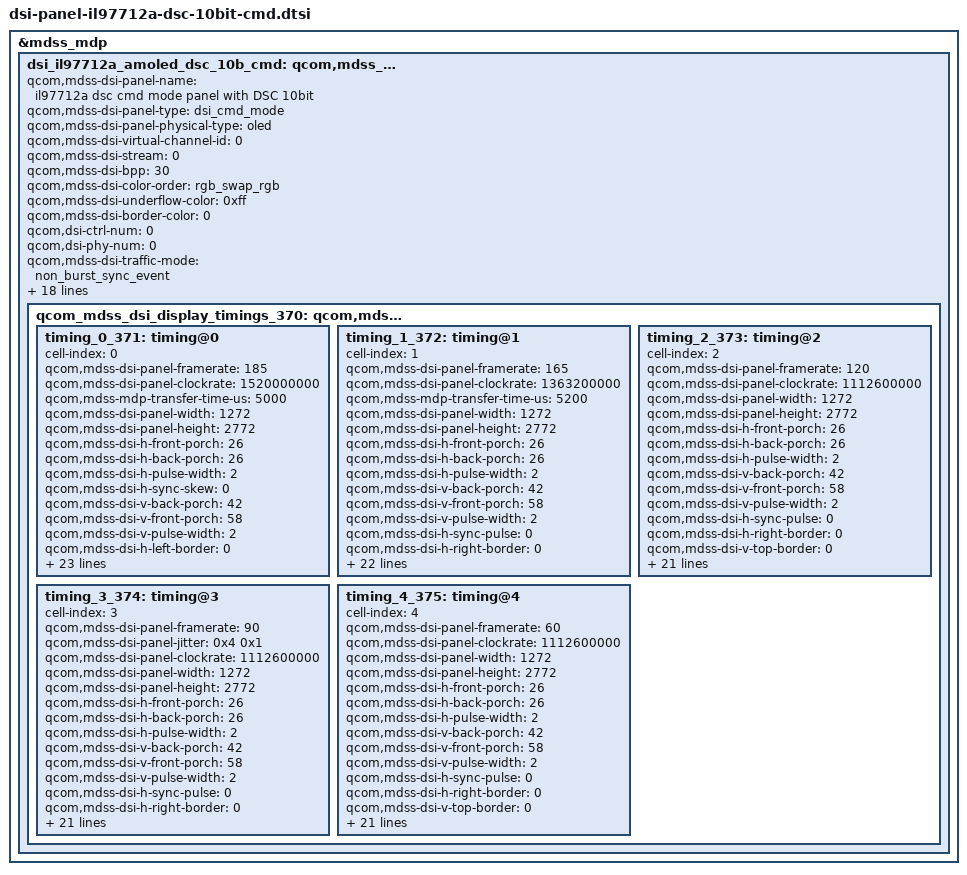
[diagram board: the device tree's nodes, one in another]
// SPDX-License-Identifier: BSD-3-Clause
/*
 * Copyright (c) Qualcomm Technologies, Inc. and/or its subsidiaries.
 */

&mdss_mdp {
	dsi_il97712a_amoled_dsc_10b_cmd: qcom,mdss_dsi_il97712a_amoled_dsc_10b_cmd {
		qcom,mdss-dsi-panel-name =
			"il97712a dsc cmd mode panel with DSC 10bit";
		qcom,mdss-dsi-panel-type = "dsi_cmd_mode";
		qcom,mdss-dsi-panel-physical-type = "oled";
		qcom,mdss-dsi-virtual-channel-id = <0>;
		qcom,mdss-dsi-stream = <0>;
		qcom,mdss-dsi-bpp = <30>;
		qcom,mdss-dsi-color-order = "rgb_swap_rgb";
		qcom,mdss-dsi-underflow-color = <0xff>;
		qcom,mdss-dsi-border-color = <0>;

		qcom,dsi-ctrl-num = <0>;
		qcom,dsi-phy-num = <0>;

		qcom,mdss-dsi-traffic-mode = "non_burst_sync_event";
		qcom,mdss-dsi-lane-map = "lane_map_0123";
		qcom,mdss-dsi-bllp-eof-power-mode;
		qcom,mdss-dsi-bllp-power-mode;
		qcom,mdss-dsi-lane-0-state;
		qcom,mdss-dsi-lane-1-state;
		qcom,mdss-dsi-lane-2-state;
		qcom,mdss-dsi-lane-3-state;
		qcom,mdss-dsi-dma-trigger = "trigger_sw";
		qcom,mdss-dsi-mdp-trigger = "none";
		qcom,mdss-dsi-reset-sequence = <1 10>, <0 10>, <1 10>;
		qcom,mdss-pan-physical-width-dimension = <71>;
		qcom,mdss-pan-physical-height-dimension = <157>;

		qcom,mdss-dsi-te-pin-select = <1>;
		qcom,mdss-dsi-wr-mem-start = <0x2c>;
		qcom,mdss-dsi-wr-mem-continue = <0x3c>;
		qcom,mdss-dsi-te-dcs-command = <1>;
		qcom,mdss-dsi-te-check-enable;
		qcom,mdss-dsi-te-using-te-pin;

		qcom_mdss_dsi_display_timings_370: qcom,mdss-dsi-display-timings {
			timing_0_371: timing@0 {
				cell-index = <0>;
				qcom,mdss-dsi-panel-framerate = <185>;
				qcom,mdss-dsi-panel-clockrate = <1520000000>;
				qcom,mdss-mdp-transfer-time-us = <5000>;
				qcom,mdss-dsi-panel-width = <1272>;
				qcom,mdss-dsi-panel-height = <2772>;
				qcom,mdss-dsi-h-front-porch = <26>;
				qcom,mdss-dsi-h-back-porch = <26>;
				qcom,mdss-dsi-h-pulse-width = <2>;
				qcom,mdss-dsi-h-sync-skew = <0>;
				qcom,mdss-dsi-v-back-porch = <42>;
				qcom,mdss-dsi-v-front-porch = <58>;
				qcom,mdss-dsi-v-pulse-width = <2>;
				qcom,mdss-dsi-h-left-border = <0>;
				qcom,mdss-dsi-h-right-border = <0>;
				qcom,mdss-dsi-v-top-border = <0>;
				qcom,mdss-dsi-v-bottom-border = <0>;
				qcom,mdss-dsi-panel-jitter = <0x4 0x1>;

				qcom,mdss-dsi-on-command = [
					39 00 00 40 00 00 04 FF 5A A5 07
					15 00 00 40 00 00 02 8A 01
					39 00 00 40 00 00 04 8B A0 00 0C
					39 00 00 00 00 00 64 81 00 00 00 00 00
					   12 00 00 AB 30 80 0A D4 04 F8 00 16
					   02 7C 02 7C 02 00 02 59 00 20 02 2E
					   00 08 00 0D 04 F4 03 ED 18 00 10 F0
					   07 10 20 00 06 0F 0F 33 0E 1C 2A 38
					   46 54 62 69 70 77 79 7B 7D 7E 02 02
					   22 00 2A 40 2A BE 3A FC 3A FA 3A F8
					   3B 38 3B 78 3B B6 4B B6 4B F4 4B F4
					   6C 34 84 74 00 00 00 00 00 00
					39 00 00 40 00 00 04 FF 5A A5 08
					15 00 00 40 00 00 02 BE 00
					15 00 00 40 00 00 02 C8 62
					39 00 00 40 00 00 04 FF 5A A5 21
					15 00 00 40 00 00 02 A4 38
					39 00 00 40 00 00 04 FF 5A A5 20
					15 00 00 40 00 00 02 C7 02
					39 00 00 40 00 00 04 FF 5A A5 00
					15 00 00 40 00 00 02 B9 01
					15 00 00 40 00 00 02 D1 08
					15 00 00 40 00 00 02 D0 00
					15 00 00 40 00 00 02 35 00
					15 00 00 40 00 00 02 53 20
					39 00 00 40 00 00 04 FF 5A A5 20
					15 00 00 40 00 00 02 C7 00
					15 00 00 40 00 00 02 D4 01
					39 00 00 40 00 00 04 FF 5A A5 00
					39 00 00 40 00 00 05 94 00 00 00 00
					39 00 00 40 00 00 04 FF 5A A5 1F
					15 00 00 40 00 00 02 80 8A
					15 00 00 40 00 00 02 81 06
					39 00 00 40 00 00 03 82 00 80
					15 00 00 40 00 00 02 87 09
					15 00 00 40 00 00 02 88 00
					39 00 00 40 00 00 06 89 41 00 04 F0 44
					39 00 00 40 00 00 03 8A 75 11
					39 00 00 40 00 00 04 8C 00 00 24
					15 00 00 40 00 00 02 8E 10
					39 00 00 40 00 00 05 96 15 35 55 01
					39 00 00 40 00 00 06 97 11 33 22 01 09
					39 00 00 40 00 00 19 83 18 24 00 00 00
					   00 00 00 00 00 00 00 00 00 00 00 00
					   00 00 00 00 00 00 00
					39 00 00 40 00 00 19 8F 39 00 00 00 00
					   00 00 00 00 00 00 00 00 00 00 00 00
					   00 00 00 00 00 00 00
					39 00 00 40 00 00 09 85 18 24 FF FF FF
					   FF FF FF
					39 00 00 40 00 00 04 91 75 00 00
					39 00 00 40 00 00 04 FF 5A A5 29
					15 00 00 40 00 00 02 80 F2
					39 00 00 40 00 00 0E 82 78 A0 B8 BC BC
					   BC BC BC BC BC BC BC BC
					39 00 00 40 00 00 0E 83 78 A0 B8 BC BC
					   BC BC BC BC BC BC BC BC
					39 00 00 40 00 00 0E 84 78 A0 B8 BC BC
					   BC BC BC BC BC BC BC BC
					39 00 00 40 00 00 0E 85 78 A0 B8 BC BC
					   BC BC BC BC BC BC BC BC
					39 00 00 00 00 00 04 FF 5A A5 00

					05 00 00 00 78 00 01 11
					05 00 00 00 14 00 01 29
				];

				qcom,mdss-dsi-off-command = [
					05 00 00 00 14 00 01 28
					05 00 00 00 78 00 01 10];
				qcom,mdss-dsi-timing-switch-command = [
					39 00 00 00 00 00 04 FF 5A A5 00
					15 00 00 40 00 00 02 D0 00
				];
				qcom,mdss-dsi-on-command-state = "dsi_lp_mode";
				qcom,mdss-dsi-off-command-state = "dsi_hs_mode";
				qcom,mdss-dsi-h-sync-pulse = <0>;
				qcom,mdss-dsi-timing-switch-command-state =
					"dsi_lp_mode";
				qcom,compression-mode = "dsc";
				qcom,mdss-dsc-version = <0x12>;
				qcom,mdss-dsc-slice-height = <22>;
				qcom,mdss-dsc-slice-width = <636>;
				qcom,mdss-dsc-slice-per-pkt = <2>;
				qcom,mdss-dsc-bit-per-component = <10>;
				qcom,mdss-dsc-bit-per-pixel = <8>;
				qcom,mdss-dsc-block-prediction-enable;
			};

			timing_1_372: timing@1 {
				cell-index = <1>;
				qcom,mdss-dsi-panel-framerate = <165>;
				qcom,mdss-dsi-panel-clockrate = <1363200000>;
				qcom,mdss-mdp-transfer-time-us = <5200>;
				qcom,mdss-dsi-panel-width = <1272>;
				qcom,mdss-dsi-panel-height = <2772>;
				qcom,mdss-dsi-h-front-porch = <26>;
				qcom,mdss-dsi-h-back-porch = <26>;
				qcom,mdss-dsi-h-pulse-width = <2>;
				qcom,mdss-dsi-v-back-porch = <42>;
				qcom,mdss-dsi-v-front-porch = <58>;
				qcom,mdss-dsi-v-pulse-width = <2>;
				qcom,mdss-dsi-h-sync-pulse = <0>;
				qcom,mdss-dsi-h-right-border = <0>;
				qcom,mdss-dsi-v-top-border = <0>;
				qcom,mdss-dsi-v-bottom-border = <0>;
				qcom,mdss-dsi-h-left-border = <0>;
				qcom,mdss-dsi-panel-jitter = <0x4 0x1>;
				qcom,mdss-dsi-on-command = [
					39 00 00 40 00 00 04 FF 5A A5 07
					15 00 00 40 00 00 02 8A 01
					39 00 00 40 00 00 04 8B A0 00 0C
					39 00 00 00 00 00 64 81 00 00 00 00 00
					   12 00 00 AB 30 80 0A D4 04 F8 00 16
					   02 7C 02 7C 02 00 02 59 00 20 02 2E
					   00 08 00 0D 04 F4 03 ED 18 00 10 F0
					   07 10 20 00 06 0F 0F 33 0E 1C 2A 38
					   46 54 62 69 70 77 79 7B 7D 7E 02 02
					   22 00 2A 40 2A BE 3A FC 3A FA 3A F8
					   3B 38 3B 78 3B B6 4B B6 4B F4 4B F4
					   6C 34 84 74 00 00 00 00 00 00
					39 00 00 40 00 00 04 FF 5A A5 08
					15 00 00 40 00 00 02 BE 00
					15 00 00 40 00 00 02 C8 62
					39 00 00 40 00 00 04 FF 5A A5 21
					15 00 00 40 00 00 02 A4 38
					39 00 00 40 00 00 04 FF 5A A5 20
					15 00 00 40 00 00 02 C7 02
					39 00 00 40 00 00 04 FF 5A A5 00
					15 00 00 40 00 00 02 B9 01
					15 00 00 40 00 00 02 D1 08
					15 00 00 40 00 00 02 D0 01
					15 00 00 40 00 00 02 35 00
					15 00 00 40 00 00 02 53 20
					39 00 00 40 00 00 04 FF 5A A5 20
					15 00 00 40 00 00 02 C7 00
					15 00 00 40 00 00 02 D4 01
					39 00 00 40 00 00 04 FF 5A A5 00
					39 00 00 40 00 00 05 94 00 00 00 00
					39 00 00 40 00 00 04 FF 5A A5 1F
					15 00 00 40 00 00 02 80 8A
					15 00 00 40 00 00 02 81 06
					39 00 00 40 00 00 03 82 00 80
					15 00 00 40 00 00 02 87 09
					15 00 00 40 00 00 02 88 00
					39 00 00 40 00 00 06 89 41 00 04 F0 44
					39 00 00 40 00 00 03 8A 75 11
					39 00 00 40 00 00 04 8C 00 00 24
					15 00 00 40 00 00 02 8E 10
					39 00 00 40 00 00 05 96 15 35 55 01
					39 00 00 40 00 00 06 97 11 33 22 01 09
					39 00 00 40 00 00 19 83 18 24 00 00 00
					   00 00 00 00 00 00 00 00 00 00 00 00
					   00 00 00 00 00 00 00
					39 00 00 40 00 00 19 8F 39 00 00 00 00
					   00 00 00 00 00 00 00 00 00 00 00 00
					   00 00 00 00 00 00 00
					39 00 00 40 00 00 09 85 18 24 FF FF FF
					   FF FF FF
					39 00 00 40 00 00 04 91 75 00 00
					39 00 00 40 00 00 04 FF 5A A5 29
					15 00 00 40 00 00 02 80 F2
					39 00 00 40 00 00 0E 82 78 A0 B8 BC BC
					   BC BC BC BC BC BC BC BC
					39 00 00 40 00 00 0E 83 78 A0 B8 BC BC
					   BC BC BC BC BC BC BC BC
					39 00 00 40 00 00 0E 84 78 A0 B8 BC BC
					   BC BC BC BC BC BC BC BC
					39 00 00 40 00 00 0E 85 78 A0 B8 BC BC
					   BC BC BC BC BC BC BC BC
					39 00 00 00 00 00 04 FF 5A A5 00

					05 00 00 00 78 00 01 11
					05 00 00 00 14 00 01 29
				];
				qcom,mdss-dsi-off-command = [
					05 00 00 00 14 00 01 28
					05 00 00 00 78 00 01 10];
				qcom,mdss-dsi-timing-switch-command = [
					39 00 00 00 00 00 04 FF 5A A5 00
					15 00 00 40 00 00 02 D0 01
				];
				qcom,mdss-dsi-on-command-state = "dsi_lp_mode";
				qcom,mdss-dsi-off-command-state = "dsi_hs_mode";
				qcom,mdss-dsi-timing-switch-command-state =
					"dsi_lp_mode";
				qcom,compression-mode = "dsc";
				qcom,mdss-dsc-version = <0x12>;
				qcom,mdss-dsc-slice-height = <22>;
				qcom,mdss-dsc-slice-width = <636>;
				qcom,mdss-dsc-slice-per-pkt = <2>;
				qcom,mdss-dsc-bit-per-component = <10>;
				qcom,mdss-dsc-bit-per-pixel = <8>;
				qcom,mdss-dsc-block-prediction-enable;
			};

			timing_2_373: timing@2 {
				cell-index = <2>;
				qcom,mdss-dsi-panel-framerate = <120>;
				qcom,mdss-dsi-panel-clockrate = <1112600000>;
				qcom,mdss-dsi-panel-width = <1272>;
				qcom,mdss-dsi-panel-height = <2772>;
				qcom,mdss-dsi-h-front-porch = <26>;
				qcom,mdss-dsi-h-back-porch = <26>;
				qcom,mdss-dsi-h-pulse-width = <2>;
				qcom,mdss-dsi-v-back-porch = <42>;
				qcom,mdss-dsi-v-front-porch = <58>;
				qcom,mdss-dsi-v-pulse-width = <2>;
				qcom,mdss-dsi-h-sync-pulse = <0>;
				qcom,mdss-dsi-h-right-border = <0>;
				qcom,mdss-dsi-v-top-border = <0>;
				qcom,mdss-dsi-v-bottom-border = <0>;
				qcom,mdss-dsi-h-left-border = <0>;
				qcom,mdss-dsi-panel-jitter = <0x4 0x1>;
				qcom,mdss-dsi-on-command = [
					39 00 00 40 00 00 04 FF 5A A5 07
					15 00 00 40 00 00 02 8A 01
					39 00 00 40 00 00 04 8B A0 00 0C
					39 00 00 00 00 00 64 81 00 00 00 00 00
					   12 00 00 AB 30 80 0A D4 04 F8 00 16
					   02 7C 02 7C 02 00 02 59 00 20 02 2E
					   00 08 00 0D 04 F4 03 ED 18 00 10 F0
					   07 10 20 00 06 0F 0F 33 0E 1C 2A 38
					   46 54 62 69 70 77 79 7B 7D 7E 02 02
					   22 00 2A 40 2A BE 3A FC 3A FA 3A F8
					   3B 38 3B 78 3B B6 4B B6 4B F4 4B F4
					   6C 34 84 74 00 00 00 00 00 00
					39 00 00 40 00 00 04 FF 5A A5 08
					15 00 00 40 00 00 02 BE 00
					15 00 00 40 00 00 02 C8 62
					39 00 00 40 00 00 04 FF 5A A5 21
					15 00 00 40 00 00 02 A4 38
					39 00 00 40 00 00 04 FF 5A A5 20
					15 00 00 40 00 00 02 C7 02
					39 00 00 40 00 00 04 FF 5A A5 00
					15 00 00 40 00 00 02 B9 01
					15 00 00 40 00 00 02 D1 08
					15 00 00 40 00 00 02 D0 03
					15 00 00 40 00 00 02 35 00
					15 00 00 40 00 00 02 53 20
					39 00 00 40 00 00 04 FF 5A A5 20
					15 00 00 40 00 00 02 C7 00
					15 00 00 40 00 00 02 D4 01
					39 00 00 40 00 00 04 FF 5A A5 00
					39 00 00 40 00 00 05 94 00 00 00 00
					39 00 00 40 00 00 04 FF 5A A5 1F
					15 00 00 40 00 00 02 80 8A
					15 00 00 40 00 00 02 81 06
					39 00 00 40 00 00 03 82 00 80
					15 00 00 40 00 00 02 87 09
					15 00 00 40 00 00 02 88 00
					39 00 00 40 00 00 06 89 41 00 04 F0 44
					39 00 00 40 00 00 03 8A 75 11
					39 00 00 40 00 00 04 8C 00 00 24
					15 00 00 40 00 00 02 8E 10
					39 00 00 40 00 00 05 96 15 35 55 01
					39 00 00 40 00 00 06 97 11 33 22 01 09
					39 00 00 40 00 00 19 83 18 24 00 00 00
					   00 00 00 00 00 00 00 00 00 00 00 00
					   00 00 00 00 00 00 00
					39 00 00 40 00 00 19 8F 39 00 00 00 00
					   00 00 00 00 00 00 00 00 00 00 00 00
					   00 00 00 00 00 00 00
					39 00 00 40 00 00 09 85 18 24 FF FF FF
					   FF FF FF
					39 00 00 40 00 00 04 91 75 00 00
					39 00 00 40 00 00 04 FF 5A A5 29
					15 00 00 40 00 00 02 80 F2
					39 00 00 40 00 00 0E 82 78 A0 B8 BC BC
					   BC BC BC BC BC BC BC BC
					39 00 00 40 00 00 0E 83 78 A0 B8 BC BC
					   BC BC BC BC BC BC BC BC
					39 00 00 40 00 00 0E 84 78 A0 B8 BC BC
					   BC BC BC BC BC BC BC BC
					39 00 00 40 00 00 0E 85 78 A0 B8 BC BC
					   BC BC BC BC BC BC BC BC
					39 00 00 00 00 00 04 FF 5A A5 00

					05 00 00 00 78 00 01 11
					05 00 00 00 14 00 01 29
				];
				qcom,mdss-dsi-off-command = [
					05 00 00 00 14 00 01 28
					05 00 00 00 78 00 01 10];
				qcom,mdss-dsi-timing-switch-command = [
					39 00 00 00 00 00 04 FF 5A A5 00
					15 00 00 40 00 00 02 D0 03
				];
				qcom,mdss-dsi-on-command-state = "dsi_lp_mode";
				qcom,mdss-dsi-off-command-state = "dsi_hs_mode";
				qcom,mdss-dsi-timing-switch-command-state =
					"dsi_lp_mode";
				qcom,compression-mode = "dsc";
				qcom,mdss-dsc-version = <0x12>;
				qcom,mdss-dsc-slice-height = <22>;
				qcom,mdss-dsc-slice-width = <636>;
				qcom,mdss-dsc-slice-per-pkt = <2>;
				qcom,mdss-dsc-bit-per-component = <10>;
				qcom,mdss-dsc-bit-per-pixel = <8>;
				qcom,mdss-dsc-block-prediction-enable;
			};

			timing_3_374: timing@3 {
				cell-index = <3>;
				qcom,mdss-dsi-panel-framerate = <90>;
				qcom,mdss-dsi-panel-jitter = <0x4 0x1>;
				qcom,mdss-dsi-panel-clockrate = <1112600000>;
				qcom,mdss-dsi-panel-width = <1272>;
				qcom,mdss-dsi-panel-height = <2772>;
				qcom,mdss-dsi-h-front-porch = <26>;
				qcom,mdss-dsi-h-back-porch = <26>;
				qcom,mdss-dsi-h-pulse-width = <2>;
				qcom,mdss-dsi-v-back-porch = <42>;
				qcom,mdss-dsi-v-front-porch = <58>;
				qcom,mdss-dsi-v-pulse-width = <2>;
				qcom,mdss-dsi-h-sync-pulse = <0>;
				qcom,mdss-dsi-h-right-border = <0>;
				qcom,mdss-dsi-v-top-border = <0>;
				qcom,mdss-dsi-v-bottom-border = <0>;
				qcom,mdss-dsi-h-left-border = <0>;
				qcom,mdss-dsi-on-command = [
					39 00 00 40 00 00 04 FF 5A A5 07
					15 00 00 40 00 00 02 8A 01
					39 00 00 40 00 00 04 8B A0 00 0C
					39 00 00 00 00 00 64 81 00 00 00 00 00
					   12 00 00 AB 30 80 0A D4 04 F8 00 16
					   02 7C 02 7C 02 00 02 59 00 20 02 2E
					   00 08 00 0D 04 F4 03 ED 18 00 10 F0
					   07 10 20 00 06 0F 0F 33 0E 1C 2A 38
					   46 54 62 69 70 77 79 7B 7D 7E 02 02
					   22 00 2A 40 2A BE 3A FC 3A FA 3A F8
					   3B 38 3B 78 3B B6 4B B6 4B F4 4B F4
					   6C 34 84 74 00 00 00 00 00 00
					39 00 00 40 00 00 04 FF 5A A5 08
					15 00 00 40 00 00 02 BE 00
					15 00 00 40 00 00 02 C8 62
					39 00 00 40 00 00 04 FF 5A A5 21
					15 00 00 40 00 00 02 A4 38
					39 00 00 40 00 00 04 FF 5A A5 20
					15 00 00 40 00 00 02 C7 02
					39 00 00 40 00 00 04 FF 5A A5 00
					15 00 00 40 00 00 02 B9 01
					15 00 00 40 00 00 02 D1 08
					15 00 00 40 00 00 02 D0 04
					15 00 00 40 00 00 02 35 00
					15 00 00 40 00 00 02 53 20
					39 00 00 40 00 00 04 FF 5A A5 20
					15 00 00 40 00 00 02 C7 00
					15 00 00 40 00 00 02 D4 01
					39 00 00 40 00 00 04 FF 5A A5 00
					39 00 00 40 00 00 05 94 00 00 00 00
					39 00 00 40 00 00 04 FF 5A A5 1F
					15 00 00 40 00 00 02 80 8A
					15 00 00 40 00 00 02 81 06
					39 00 00 40 00 00 03 82 00 80
					15 00 00 40 00 00 02 87 09
					15 00 00 40 00 00 02 88 00
					39 00 00 40 00 00 06 89 41 00 04 F0 44
					39 00 00 40 00 00 03 8A 75 11
					39 00 00 40 00 00 04 8C 00 00 24
					15 00 00 40 00 00 02 8E 10
					39 00 00 40 00 00 05 96 15 35 55 01
					39 00 00 40 00 00 06 97 11 33 22 01 09
					39 00 00 40 00 00 19 83 18 24 00 00 00
					   00 00 00 00 00 00 00 00 00 00 00 00
					   00 00 00 00 00 00 00
					39 00 00 40 00 00 19 8F 39 00 00 00 00
					   00 00 00 00 00 00 00 00 00 00 00 00
					   00 00 00 00 00 00 00
					39 00 00 40 00 00 09 85 18 24 FF FF FF
					   FF FF FF
					39 00 00 40 00 00 04 91 75 00 00
					39 00 00 40 00 00 04 FF 5A A5 29
					15 00 00 40 00 00 02 80 F2
					39 00 00 40 00 00 0E 82 78 A0 B8 BC BC
					   BC BC BC BC BC BC BC BC
					39 00 00 40 00 00 0E 83 78 A0 B8 BC BC
					   BC BC BC BC BC BC BC BC
					39 00 00 40 00 00 0E 84 78 A0 B8 BC BC
					   BC BC BC BC BC BC BC BC
					39 00 00 40 00 00 0E 85 78 A0 B8 BC BC
					   BC BC BC BC BC BC BC BC
					39 00 00 00 00 00 04 FF 5A A5 00

					05 00 00 00 78 00 01 11
					05 00 00 00 14 00 01 29
				];
				qcom,mdss-dsi-off-command = [
					05 00 00 00 14 00 01 28
					05 00 00 00 78 00 01 10];
				qcom,mdss-dsi-timing-switch-command = [
					39 00 00 40 00 00 04 FF 5A A5 00
					15 00 00 00 00 00 02 D0 04
				];
				qcom,mdss-dsi-on-command-state = "dsi_lp_mode";
				qcom,mdss-dsi-off-command-state = "dsi_hs_mode";
				qcom,mdss-dsi-timing-switch-command-state =
					"dsi_lp_mode";
				qcom,compression-mode = "dsc";
				qcom,mdss-dsc-version = <0x12>;
				qcom,mdss-dsc-slice-height = <22>;
				qcom,mdss-dsc-slice-width = <636>;
				qcom,mdss-dsc-slice-per-pkt = <2>;
				qcom,mdss-dsc-bit-per-component = <10>;
				qcom,mdss-dsc-bit-per-pixel = <8>;
				qcom,mdss-dsc-block-prediction-enable;
			};

			timing_4_375: timing@4 {
				cell-index = <4>;
				qcom,mdss-dsi-panel-framerate = <60>;
				qcom,mdss-dsi-panel-clockrate = <1112600000>;
				qcom,mdss-dsi-panel-width = <1272>;
				qcom,mdss-dsi-panel-height = <2772>;
				qcom,mdss-dsi-h-front-porch = <26>;
				qcom,mdss-dsi-h-back-porch = <26>;
				qcom,mdss-dsi-h-pulse-width = <2>;
				qcom,mdss-dsi-v-back-porch = <42>;
				qcom,mdss-dsi-v-front-porch = <58>;
				qcom,mdss-dsi-v-pulse-width = <2>;
				qcom,mdss-dsi-h-sync-pulse = <0>;
				qcom,mdss-dsi-h-right-border = <0>;
				qcom,mdss-dsi-v-top-border = <0>;
				qcom,mdss-dsi-v-bottom-border = <0>;
				qcom,mdss-dsi-h-left-border = <0>;
				qcom,mdss-dsi-panel-jitter = <0x4 0x1>;
				qcom,mdss-dsi-on-command = [
					39 00 00 40 00 00 04 FF 5A A5 07
					15 00 00 40 00 00 02 8A 01
					39 00 00 40 00 00 04 8B A0 00 0C
					39 00 00 00 00 00 64 81 00 00 00 00 00
					   12 00 00 AB 30 80 0A D4 04 F8 00 16
					   02 7C 02 7C 02 00 02 59 00 20 02 2E
					   00 08 00 0D 04 F4 03 ED 18 00 10 F0
					   07 10 20 00 06 0F 0F 33 0E 1C 2A 38
					   46 54 62 69 70 77 79 7B 7D 7E 02 02
					   22 00 2A 40 2A BE 3A FC 3A FA 3A F8
					   3B 38 3B 78 3B B6 4B B6 4B F4 4B F4
					   6C 34 84 74 00 00 00 00 00 00
					39 00 00 40 00 00 04 FF 5A A5 08
					15 00 00 40 00 00 02 BE 00
					15 00 00 40 00 00 02 C8 62
					39 00 00 40 00 00 04 FF 5A A5 21
					15 00 00 40 00 00 02 A4 38
					39 00 00 40 00 00 04 FF 5A A5 20
					15 00 00 40 00 00 02 C7 02
					39 00 00 40 00 00 04 FF 5A A5 00
					15 00 00 40 00 00 02 B9 01
					15 00 00 40 00 00 02 D1 08
					15 00 00 40 00 00 02 D0 03
					15 00 00 40 00 00 02 35 00
					15 00 00 40 00 00 02 53 20
					39 00 00 40 00 00 04 FF 5A A5 20
					15 00 00 40 00 00 02 C7 00
					15 00 00 40 00 00 02 D4 01
					39 00 00 40 00 00 04 FF 5A A5 00
					39 00 00 40 00 00 05 94 00 00 00 00
					39 00 00 40 00 00 04 FF 5A A5 1F
					15 00 00 40 00 00 02 80 8A
					15 00 00 40 00 00 02 81 06
					39 00 00 40 00 00 03 82 00 80
					15 00 00 40 00 00 02 87 09
					15 00 00 40 00 00 02 88 00
					39 00 00 40 00 00 06 89 41 00 04 F0 44
					39 00 00 40 00 00 03 8A 75 11
					39 00 00 40 00 00 04 8C 00 00 24
					15 00 00 40 00 00 02 8E 10
					39 00 00 40 00 00 05 96 15 35 55 01
					39 00 00 40 00 00 06 97 11 33 22 01 09
					39 00 00 40 00 00 19 83 18 24 00 00 00
					   00 00 00 00 00 00 00 00 00 00 00 00
					   00 00 00 00 00 00 00
					39 00 00 40 00 00 19 8F 39 00 00 00 00
					   00 00 00 00 00 00 00 00 00 00 00 00
					   00 00 00 00 00 00 00
					39 00 00 40 00 00 09 85 18 24 FF FF FF
					   FF FF FF
					39 00 00 40 00 00 04 91 75 00 00
					39 00 00 40 00 00 04 FF 5A A5 29
					15 00 00 40 00 00 02 80 F2
					39 00 00 40 00 00 0E 82 78 A0 B8 BC BC
					   BC BC BC BC BC BC BC BC
					39 00 00 40 00 00 0E 83 78 A0 B8 BC BC
					   BC BC BC BC BC BC BC BC
					39 00 00 40 00 00 0E 84 78 A0 B8 BC BC
					   BC BC BC BC BC BC BC BC
					39 00 00 40 00 00 0E 85 78 A0 B8 BC BC
					   BC BC BC BC BC BC BC BC
					39 00 00 00 00 00 04 FF 5A A5 00

					05 00 00 00 78 00 01 11
					05 00 00 00 14 00 01 29
				];
				qcom,mdss-dsi-off-command = [
					05 00 00 00 14 00 01 28
					05 00 00 00 78 00 01 10];
				qcom,mdss-dsi-timing-switch-command = [
					39 00 00 40 00 00 04 FF 5A A5 00
					15 00 00 00 00 00 02 D0 03
				];
				qcom,mdss-dsi-on-command-state = "dsi_lp_mode";
				qcom,mdss-dsi-off-command-state = "dsi_hs_mode";
				qcom,mdss-dsi-timing-switch-command-state =
					"dsi_lp_mode";
				qcom,compression-mode = "dsc";
				qcom,mdss-dsc-version = <0x12>;
				qcom,mdss-dsc-slice-height = <22>;
				qcom,mdss-dsc-slice-width = <636>;
				qcom,mdss-dsc-slice-per-pkt = <2>;
				qcom,mdss-dsc-bit-per-component = <10>;
				qcom,mdss-dsc-bit-per-pixel = <8>;
				qcom,mdss-dsc-block-prediction-enable;
			};
		};
	};
};
